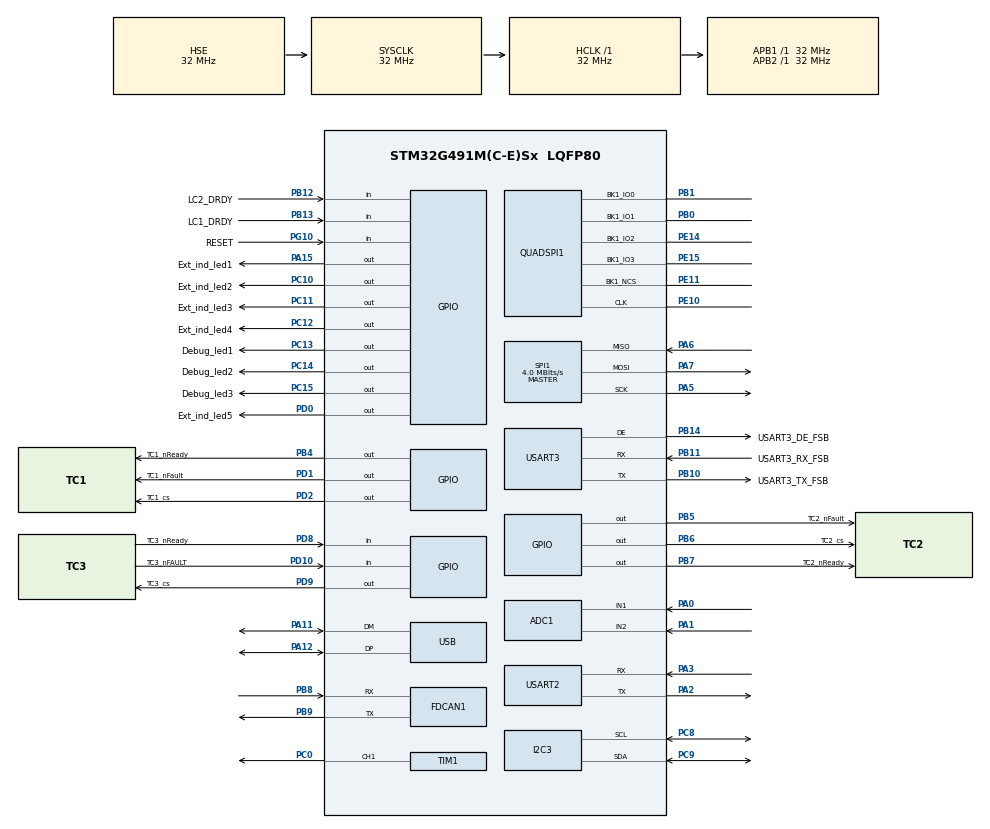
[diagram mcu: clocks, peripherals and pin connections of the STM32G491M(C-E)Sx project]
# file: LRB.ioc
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ADC1.Channel-0\#ChannelRegularConversion=ADC_CHANNEL_1
ADC1.NbrOfConversionFlag=1
ADC1.OffsetNumber-0\#ChannelRegularConversion=ADC_OFFSET_NONE
ADC1.Rank-0\#ChannelRegularConversion=1
ADC1.SamplingTime-0\#ChannelRegularConversion=ADC_SAMPLETIME_2CYCLES_5
ADC1.SingleDiff-0\#ChannelRegularConversion=ADC_DIFFERENTIAL_ENDED
ADC1.master=1
Dma.I2C3_RX.0.Direction=DMA_PERIPH_TO_MEMORY
Dma.I2C3_RX.0.EventEnable=DISABLE
Dma.I2C3_RX.0.Instance=DMA1_Channel1
Dma.I2C3_RX.0.MemDataAlignment=DMA_MDATAALIGN_BYTE
Dma.I2C3_RX.0.MemInc=DMA_MINC_ENABLE
Dma.I2C3_RX.0.Mode=DMA_NORMAL
Dma.I2C3_RX.0.PeriphDataAlignment=DMA_PDATAALIGN_BYTE
Dma.I2C3_RX.0.PeriphInc=DMA_PINC_DISABLE
Dma.I2C3_RX.0.Polarity=HAL_DMAMUX_REQ_GEN_RISING
Dma.I2C3_RX.0.Priority=DMA_PRIORITY_LOW
Dma.I2C3_RX.0.RequestNumber=1
Dma.I2C3_RX.0.SignalID=NONE
Dma.I2C3_RX.0.SyncEnable=DISABLE
Dma.I2C3_RX.0.SyncPolarity=HAL_DMAMUX_SYNC_NO_EVENT
Dma.I2C3_RX.0.SyncRequestNumber=1
Dma.I2C3_RX.0.SyncSignalID=NONE
Dma.I2C3_TX.1.Direction=DMA_MEMORY_TO_PERIPH
Dma.I2C3_TX.1.EventEnable=DISABLE
Dma.I2C3_TX.1.Instance=DMA1_Channel2
Dma.I2C3_TX.1.MemDataAlignment=DMA_MDATAALIGN_BYTE
Dma.I2C3_TX.1.MemInc=DMA_MINC_ENABLE
Dma.I2C3_TX.1.Mode=DMA_NORMAL
Dma.I2C3_TX.1.PeriphDataAlignment=DMA_PDATAALIGN_BYTE
Dma.I2C3_TX.1.PeriphInc=DMA_PINC_DISABLE
Dma.I2C3_TX.1.Polarity=HAL_DMAMUX_REQ_GEN_RISING
Dma.I2C3_TX.1.Priority=DMA_PRIORITY_LOW
Dma.I2C3_TX.1.RequestNumber=1
Dma.I2C3_TX.1.SignalID=NONE
Dma.I2C3_TX.1.SyncEnable=DISABLE
Dma.I2C3_TX.1.SyncPolarity=HAL_DMAMUX_SYNC_NO_EVENT
Dma.I2C3_TX.1.SyncRequestNumber=1
Dma.I2C3_TX.1.SyncSignalID=NONE
Dma.Request0=I2C3_RX
Dma.Request1=I2C3_TX
Dma.Request2=SPI1_RX
Dma.Request3=SPI1_TX
Dma.SPI1_RX.2.Direction=DMA_PERIPH_TO_MEMORY
Dma.SPI1_RX.2.EventEnable=DISABLE
Dma.SPI1_RX.2.Instance=DMA1_Channel3
Dma.SPI1_RX.2.MemDataAlignment=DMA_MDATAALIGN_BYTE
Dma.SPI1_RX.2.MemInc=DMA_MINC_ENABLE
Dma.SPI1_RX.2.Mode=DMA_NORMAL
Dma.SPI1_RX.2.PeriphDataAlignment=DMA_PDATAALIGN_BYTE
Dma.SPI1_RX.2.PeriphInc=DMA_PINC_DISABLE
Dma.SPI1_RX.2.Polarity=HAL_DMAMUX_REQ_GEN_RISING
Dma.SPI1_RX.2.Priority=DMA_PRIORITY_LOW
Dma.SPI1_RX.2.RequestNumber=1
Dma.SPI1_RX.2.SignalID=NONE
Dma.SPI1_RX.2.SyncEnable=DISABLE
Dma.SPI1_RX.2.SyncPolarity=HAL_DMAMUX_SYNC_NO_EVENT
Dma.SPI1_RX.2.SyncRequestNumber=1
Dma.SPI1_RX.2.SyncSignalID=NONE
Dma.SPI1_TX.3.Direction=DMA_MEMORY_TO_PERIPH
Dma.SPI1_TX.3.EventEnable=DISABLE
Dma.SPI1_TX.3.Instance=DMA1_Channel4
Dma.SPI1_TX.3.MemDataAlignment=DMA_MDATAALIGN_BYTE
Dma.SPI1_TX.3.MemInc=DMA_MINC_ENABLE
Dma.SPI1_TX.3.Mode=DMA_NORMAL
Dma.SPI1_TX.3.PeriphDataAlignment=DMA_PDATAALIGN_BYTE
Dma.SPI1_TX.3.PeriphInc=DMA_PINC_DISABLE
Dma.SPI1_TX.3.Polarity=HAL_DMAMUX_REQ_GEN_RISING
Dma.SPI1_TX.3.Priority=DMA_PRIORITY_LOW
Dma.SPI1_TX.3.RequestNumber=1
Dma.SPI1_TX.3.SignalID=NONE
Dma.SPI1_TX.3.SyncEnable=DISABLE
Dma.SPI1_TX.3.SyncPolarity=HAL_DMAMUX_SYNC_NO_EVENT
Dma.SPI1_TX.3.SyncRequestNumber=1
Dma.SPI1_TX.3.SyncSignalID=NONE
FDCAN1.CalculateBaudRateNominal=666666
FDCAN1.CalculateTimeBitNominal=1500
FDCAN1.CalculateTimeQuantumNominal=500.0
FREERTOS.Tasks01=defaultTask,0,192,StartDefaultTask,Default,NULL,Dynamic,NULL,NULL
FREERTOS.configMINIMAL_STACK_SIZE=192
FREERTOS.configTOTAL_HEAP_SIZE=65536
FREERTOS.configUSE_NEWLIB_REENTRANT=1
FREERTOS.configUSE_TIMERS=1
I2C3.Timing=0x00B07CB4
Mcu.Family=STM32G4
Mcu.Name=STM32G491M(C-E)Sx
Mcu.Package=LQFP80
NVIC.DMA1_Channel1_IRQn=true\:5\:0\:false\:false\:true\:true\:false\:true\:true
NVIC.DMA1_Channel2_IRQn=true\:5\:0\:false\:false\:true\:true\:false\:true\:true
NVIC.DMA1_Channel3_IRQn=true\:5\:0\:false\:false\:true\:true\:false\:true\:true
NVIC.DMA1_Channel4_IRQn=true\:5\:0\:false\:false\:true\:true\:false\:true\:true
NVIC.I2C3_ER_IRQn=true\:5\:0\:false\:false\:true\:true\:true\:true\:true
NVIC.I2C3_EV_IRQn=true\:5\:0\:false\:false\:true\:true\:true\:true\:true
NVIC.PriorityGroup=NVIC_PRIORITYGROUP_4
NVIC.SPI1_IRQn=true\:5\:0\:false\:false\:true\:true\:true\:true\:true
NVIC.TIM2_IRQn=true\:15\:0\:false\:false\:true\:false\:false\:true\:true
NVIC.TimeBase=TIM2_IRQn
NVIC.TimeBaseIP=TIM2
NVIC.USART2_IRQn=true\:5\:0\:false\:false\:true\:true\:true\:true\:true
PA0.Mode=IN1-Differential
PA0.Signal=ADC1_IN1
PA1.Mode=IN1-Differential
PA1.Signal=ADC1_IN2
PA11.Mode=Device
PA11.Signal=USB_DM
PA12.Mode=Device
PA12.Signal=USB_DP
PA13.Mode=Trace_Asynchronous_SW
PA13.Signal=SYS_JTMS-SWDIO
PA14.Mode=Trace_Asynchronous_SW
PA14.Signal=SYS_JTCK-SWCLK
PA15.GPIO_Label=Ext_ind_led1
PA15.Signal=GPIO_Output
PA2.Mode=Asynchronous
PA2.Signal=USART2_TX
PA3.Mode=Asynchronous
PA3.Signal=USART2_RX
PA5.GPIO_Speed=GPIO_SPEED_FREQ_VERY_HIGH
PA5.Mode=Full_Duplex_Master
PA5.Signal=SPI1_SCK
PA6.GPIO_Speed=GPIO_SPEED_FREQ_VERY_HIGH
PA6.Mode=Full_Duplex_Master
PA6.Signal=SPI1_MISO
PA7.GPIO_Speed=GPIO_SPEED_FREQ_VERY_HIGH
PA7.Mode=Full_Duplex_Master
PA7.Signal=SPI1_MOSI
PB0.Mode=Single Bank 1
PB0.Signal=QUADSPI1_BK1_IO1
PB1.Mode=Single Bank 1
PB1.Signal=QUADSPI1_BK1_IO0
PB10.GPIO_Label=USART3_TX_FSB
PB10.Mode=Asynchronous
PB10.Signal=USART3_TX
PB11.GPIO_Label=USART3_RX_FSB
PB11.Mode=Asynchronous
PB11.Signal=USART3_RX
PB12.GPIO_Label=LC2_DRDY
PB12.Signal=GPIO_Input
PB13.GPIO_Label=LC1_DRDY
PB13.Signal=GPIO_Input
PB14.GPIO_Label=USART3_DE_FSB
PB14.Mode=Hardware Flow Control (RS485)
PB14.Signal=USART3_DE
PB3.Mode=Trace_Asynchronous_SW
PB3.Signal=SYS_JTDO-SWO
PB4.GPIO_Label=TC1_nReady
PB4.Signal=GPIO_Output
PB5.GPIO_Label=TC2_nFault
PB5.Signal=GPIO_Output
PB6.GPIO_Label=TC2_cs
PB6.Signal=GPIO_Output
PB7.GPIO_Label=TC2_nReady
PB7.Signal=GPIO_Output
PB8-BOOT0.Mode=FDCAN_Activate
PB8-BOOT0.Signal=FDCAN1_RX
PB9.Mode=FDCAN_Activate
PB9.Signal=FDCAN1_TX
PC0.Signal=S_TIM1_CH1
PC10.GPIO_Label=Ext_ind_led2
PC10.Signal=GPIO_Output
PC11.GPIO_Label=Ext_ind_led3
PC11.Signal=GPIO_Output
PC12.GPIO_Label=Ext_ind_led4
PC12.Signal=GPIO_Output
PC13.GPIO_Label=Debug_led1
PC13.Signal=GPIO_Output
PC14-OSC32_IN.GPIO_Label=Debug_led2
PC14-OSC32_IN.Signal=GPIO_Output
PC15-OSC32_OUT.GPIO_Label=Debug_led3
PC15-OSC32_OUT.Signal=GPIO_Output
PC8.GPIO_Pu=GPIO_PULLUP
PC8.GPIO_Speed=GPIO_SPEED_FREQ_VERY_HIGH
PC8.Mode=I2C
PC8.Signal=I2C3_SCL
PC9.GPIO_Pu=GPIO_PULLUP
PC9.GPIO_Speed=GPIO_SPEED_FREQ_VERY_HIGH
PC9.Mode=I2C
PC9.Signal=I2C3_SDA
PD0.GPIO_Label=Ext_ind_led5
PD0.Signal=GPIO_Output
PD1.GPIO_Label=TC1_nFault
PD1.Signal=GPIO_Output
PD10.GPIO_Label=TC3_nFAULT
PD10.Signal=GPIO_Input
PD2.GPIO_Label=TC1_cs
PD2.Signal=GPIO_Output
PD8.GPIO_Label=TC3_nReady
PD8.Signal=GPIO_Input
PD9.GPIO_Label=TC3_cs
PD9.Signal=GPIO_Output
PE10.Mode=Single Bank 1
PE10.Signal=QUADSPI1_CLK
PE11.Mode=Single Bank 1
PE11.Signal=QUADSPI1_BK1_NCS
PE14.Mode=Single Bank 1
PE14.Signal=QUADSPI1_BK1_IO2
PE15.Mode=Single Bank 1
PE15.Signal=QUADSPI1_BK1_IO3
PF0-OSC_IN.Mode=HSE-External-Oscillator
PF0-OSC_IN.Signal=RCC_OSC_IN
PF1-OSC_OUT.Mode=HSE-External-Oscillator
PF1-OSC_OUT.Signal=RCC_OSC_OUT
PG10-NRST.GPIO_Label=RESET
PG10-NRST.Signal=GPIO_Input
ProjectManager.HeapSize=0x200
ProjectManager.StackSize=0x400
ProjectManager.TargetToolchain=STM32CubeIDE
RCC.ADC12Freq_Value=32000000
RCC.ADC345Freq_Value=32000000
RCC.AHBFreq_Value=32000000
RCC.APB1Freq_Value=32000000
RCC.APB1TimFreq_Value=32000000
RCC.APB2Freq_Value=32000000
RCC.APB2TimFreq_Value=32000000
RCC.CortexFreq_Value=32000000
RCC.EXTERNAL_CLOCK_VALUE=12288000
RCC.HCLKFreq_Value=32000000
RCC.HSE_VALUE=32000000
RCC.HSI48_VALUE=48000000
RCC.HSI_VALUE=16000000
RCC.LSE_VALUE=32768
RCC.PLLSourceVirtual=RCC_PLLSOURCE_HSE
RCC.SYSCLKFreq_VALUE=32000000
RCC.SYSCLKSource=RCC_SYSCLKSOURCE_HSE
RCC.VCOOutputFreq_Value=256000000
SH.S_TIM1_CH1.0=TIM1_CH1,PWM Generation1 CH1
SPI1.BaudRatePrescaler=SPI_BAUDRATEPRESCALER_8
SPI1.CLKPhase=SPI_PHASE_2EDGE
SPI1.CLKPolarity=SPI_POLARITY_HIGH
SPI1.CalculateBaudRate=4.0 MBits/s
SPI1.DataSize=SPI_DATASIZE_8BIT
SPI1.Direction=SPI_DIRECTION_2LINES
SPI1.Mode=SPI_MODE_MASTER
SPI1.VirtualType=VM_MASTER
TIM1.Channel-PWM\ Generation1\ CH1=TIM_CHANNEL_1
TIM3.Prescaler=10000
USART2.VirtualMode-Asynchronous=VM_ASYNC
USART3.VirtualMode-Asynchronous=VM_ASYNC
USART3.VirtualMode-Hardware\ Flow\ Control\ (RS485)=VM_ASYNC
VP_CRC_VS_CRC.Mode=CRC_Activate
VP_FREERTOS_VS_CMSIS_V1.Mode=CMSIS_V1
VP_SYS_VS_DBSignals.Mode=DisableDeadBatterySignals
VP_SYS_VS_tim2.Mode=TIM2
VP_TIM3_VS_ClockSourceINT.Mode=Internal
board=custom

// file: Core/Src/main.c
/* USER CODE BEGIN Header */
/**
  ******************************************************************************
  * @file           : main.c
  * @brief          : Main program body
  ******************************************************************************
  * @attention
  *
  * Copyright (c) 2026 STMicroelectronics.
  * All rights reserved.
  *
  * This software is licensed under terms that can be found in the LICENSE file
  * in the root directory of this software component.
  * If no LICENSE file comes with this software, it is provided AS-IS.
  *
  ******************************************************************************
  */
/* USER CODE END Header */
#include "main.h"
#include "cmsis_os.h"

/* USER CODE BEGIN Includes */
#include "RunInterface.hpp"
//#define USE_FULL_LL_DRIVER
/* USER CODE END Includes */

ADC_HandleTypeDef hadc1;

CRC_HandleTypeDef hcrc;

FDCAN_HandleTypeDef hfdcan1;

I2C_HandleTypeDef hi2c3;
DMA_HandleTypeDef hdma_i2c3_rx;
DMA_HandleTypeDef hdma_i2c3_tx;

QSPI_HandleTypeDef hqspi1;

SPI_HandleTypeDef hspi1;
DMA_HandleTypeDef hdma_spi1_rx;
DMA_HandleTypeDef hdma_spi1_tx;

TIM_HandleTypeDef htim1;
TIM_HandleTypeDef htim3;

UART_HandleTypeDef huart3;

PCD_HandleTypeDef hpcd_USB_FS;

osThreadId defaultTaskHandle;

void SystemClock_Config(void);
static void MX_GPIO_Init(void);
static void MX_DMA_Init(void);
static void MX_QUADSPI1_Init(void);
static void MX_SPI1_Init(void);
static void MX_USB_PCD_Init(void);
static void MX_USART2_UART_Init(void);
static void MX_USART3_UART_Init(void);
static void MX_ADC1_Init(void);
static void MX_I2C3_Init(void);
static void MX_TIM1_Init(void);
static void MX_CRC_Init(void);
static void MX_TIM3_Init(void);
static void MX_FDCAN1_Init(void);
void StartDefaultTask(void const * argument);

int main(void)
{

  /* MCU Configuration--------------------------------------------------------*/

  /* Reset of all peripherals, Initializes the Flash interface and the Systick. */
  HAL_Init();

  /* Configure the system clock */
  SystemClock_Config();

  /* Initialize all configured peripherals */
  MX_GPIO_Init();
  MX_DMA_Init();
  MX_QUADSPI1_Init();
  MX_SPI1_Init();
  MX_USB_PCD_Init();
  MX_USART2_UART_Init();
  MX_USART3_UART_Init();
  MX_ADC1_Init();
  MX_I2C3_Init();
  MX_TIM1_Init();
  MX_CRC_Init();
  MX_TIM3_Init();
  MX_FDCAN1_Init();
  /* USER CODE BEGIN 2 */
#if (configGENERATE_RUN_TIME_STATS == 1)
  MX_TIM3_Init();		// Replace TIM2 with your selected timer
#endif
  /* USER CODE END 2 */

  /* Create the thread(s) */
  /* definition and creation of defaultTask */
  osThreadDef(defaultTask, StartDefaultTask, osPriorityNormal, 0, 192);
  defaultTaskHandle = osThreadCreate(osThread(defaultTask), NULL);

  /* USER CODE BEGIN RTOS_THREADS */
  /* add threads, ... */
  run_interface();
  /* USER CODE END RTOS_THREADS */

  /* Start scheduler */
  osKernelStart();

  /* We should never get here as control is now taken by the scheduler */

  /* Infinite loop */
  while (1)
  {

  }
}

void SystemClock_Config(void)
{
  RCC_OscInitTypeDef RCC_OscInitStruct = {0};
  RCC_ClkInitTypeDef RCC_ClkInitStruct = {0};

  /** Configure the main internal regulator output voltage
  */
  HAL_PWREx_ControlVoltageScaling(PWR_REGULATOR_VOLTAGE_SCALE1);

  /** Initializes the RCC Oscillators according to the specified parameters
  * in the RCC_OscInitTypeDef structure.
  */
  RCC_OscInitStruct.OscillatorType = RCC_OSCILLATORTYPE_HSI48|RCC_OSCILLATORTYPE_HSE;
  RCC_OscInitStruct.HSEState = RCC_HSE_ON;
  RCC_OscInitStruct.HSI48State = RCC_HSI48_ON;
  RCC_OscInitStruct.PLL.PLLState = RCC_PLL_NONE;
  if (HAL_RCC_OscConfig(&RCC_OscInitStruct) != HAL_OK)
  {
    Error_Handler();
  }

  /** Initializes the CPU, AHB and APB buses clocks
  */
  RCC_ClkInitStruct.ClockType = RCC_CLOCKTYPE_HCLK|RCC_CLOCKTYPE_SYSCLK
                              |RCC_CLOCKTYPE_PCLK1|RCC_CLOCKTYPE_PCLK2;
  RCC_ClkInitStruct.SYSCLKSource = RCC_SYSCLKSOURCE_HSE;
  RCC_ClkInitStruct.AHBCLKDivider = RCC_SYSCLK_DIV1;
  RCC_ClkInitStruct.APB1CLKDivider = RCC_HCLK_DIV1;
  RCC_ClkInitStruct.APB2CLKDivider = RCC_HCLK_DIV1;

  if (HAL_RCC_ClockConfig(&RCC_ClkInitStruct, FLASH_LATENCY_1) != HAL_OK)
  {
    Error_Handler();
  }
}

static void MX_ADC1_Init(void)
{

  ADC_MultiModeTypeDef multimode = {0};
  ADC_ChannelConfTypeDef sConfig = {0};

  /** Common config
  */
  hadc1.Instance = ADC1;
  hadc1.Init.ClockPrescaler = ADC_CLOCK_SYNC_PCLK_DIV2;
  hadc1.Init.Resolution = ADC_RESOLUTION_12B;
  hadc1.Init.DataAlign = ADC_DATAALIGN_RIGHT;
  hadc1.Init.GainCompensation = 0;
  hadc1.Init.ScanConvMode = ADC_SCAN_DISABLE;
  hadc1.Init.EOCSelection = ADC_EOC_SINGLE_CONV;
  hadc1.Init.LowPowerAutoWait = DISABLE;
  hadc1.Init.ContinuousConvMode = DISABLE;
  hadc1.Init.NbrOfConversion = 1;
  hadc1.Init.DiscontinuousConvMode = DISABLE;
  hadc1.Init.ExternalTrigConv = ADC_SOFTWARE_START;
  hadc1.Init.ExternalTrigConvEdge = ADC_EXTERNALTRIGCONVEDGE_NONE;
  hadc1.Init.DMAContinuousRequests = DISABLE;
  hadc1.Init.Overrun = ADC_OVR_DATA_PRESERVED;
  hadc1.Init.OversamplingMode = DISABLE;
  if (HAL_ADC_Init(&hadc1) != HAL_OK)
  {
    Error_Handler();
  }

  /** Configure the ADC multi-mode
  */
  multimode.Mode = ADC_MODE_INDEPENDENT;
  if (HAL_ADCEx_MultiModeConfigChannel(&hadc1, &multimode) != HAL_OK)
  {
    Error_Handler();
  }

  /** Configure Regular Channel
  */
  sConfig.Channel = ADC_CHANNEL_1;
  sConfig.Rank = ADC_REGULAR_RANK_1;
  sConfig.SamplingTime = ADC_SAMPLETIME_2CYCLES_5;
  sConfig.SingleDiff = ADC_DIFFERENTIAL_ENDED;
  sConfig.OffsetNumber = ADC_OFFSET_NONE;
  sConfig.Offset = 0;
  if (HAL_ADC_ConfigChannel(&hadc1, &sConfig) != HAL_OK)
  {
    Error_Handler();
  }

}

static void MX_CRC_Init(void)
{

  hcrc.Instance = CRC;
  hcrc.Init.DefaultPolynomialUse = DEFAULT_POLYNOMIAL_ENABLE;
  hcrc.Init.DefaultInitValueUse = DEFAULT_INIT_VALUE_ENABLE;
  hcrc.Init.InputDataInversionMode = CRC_INPUTDATA_INVERSION_NONE;
  hcrc.Init.OutputDataInversionMode = CRC_OUTPUTDATA_INVERSION_DISABLE;
  hcrc.InputDataFormat = CRC_INPUTDATA_FORMAT_BYTES;
  if (HAL_CRC_Init(&hcrc) != HAL_OK)
  {
    Error_Handler();
  }

}

static void MX_FDCAN1_Init(void)
{

  hfdcan1.Instance = FDCAN1;
  hfdcan1.Init.ClockDivider = FDCAN_CLOCK_DIV1;
  hfdcan1.Init.FrameFormat = FDCAN_FRAME_CLASSIC;
  hfdcan1.Init.Mode = FDCAN_MODE_NORMAL;
  hfdcan1.Init.AutoRetransmission = DISABLE;
  hfdcan1.Init.TransmitPause = DISABLE;
  hfdcan1.Init.ProtocolException = DISABLE;
  hfdcan1.Init.NominalPrescaler = 16;
  hfdcan1.Init.NominalSyncJumpWidth = 1;
  hfdcan1.Init.NominalTimeSeg1 = 1;
  hfdcan1.Init.NominalTimeSeg2 = 1;
  hfdcan1.Init.DataPrescaler = 1;
  hfdcan1.Init.DataSyncJumpWidth = 1;
  hfdcan1.Init.DataTimeSeg1 = 1;
  hfdcan1.Init.DataTimeSeg2 = 1;
  hfdcan1.Init.StdFiltersNbr = 0;
  hfdcan1.Init.ExtFiltersNbr = 0;
  hfdcan1.Init.TxFifoQueueMode = FDCAN_TX_FIFO_OPERATION;
  if (HAL_FDCAN_Init(&hfdcan1) != HAL_OK)
  {
    Error_Handler();
  }

}

static void MX_I2C3_Init(void)
{

  hi2c3.Instance = I2C3;
  hi2c3.Init.Timing = 0x00B07CB4;
  hi2c3.Init.OwnAddress1 = 0;
  hi2c3.Init.AddressingMode = I2C_ADDRESSINGMODE_7BIT;
  hi2c3.Init.DualAddressMode = I2C_DUALADDRESS_DISABLE;
  hi2c3.Init.OwnAddress2 = 0;
  hi2c3.Init.OwnAddress2Masks = I2C_OA2_NOMASK;
  hi2c3.Init.GeneralCallMode = I2C_GENERALCALL_DISABLE;
  hi2c3.Init.NoStretchMode = I2C_NOSTRETCH_DISABLE;
  if (HAL_I2C_Init(&hi2c3) != HAL_OK)
  {
    Error_Handler();
  }

  /** Configure Analogue filter
  */
  if (HAL_I2CEx_ConfigAnalogFilter(&hi2c3, I2C_ANALOGFILTER_ENABLE) != HAL_OK)
  {
    Error_Handler();
  }

  /** Configure Digital filter
  */
  if (HAL_I2CEx_ConfigDigitalFilter(&hi2c3, 0) != HAL_OK)
  {
    Error_Handler();
  }

}

static void MX_QUADSPI1_Init(void)
{

  /* QUADSPI1 parameter configuration*/
  hqspi1.Instance = QUADSPI;
  hqspi1.Init.ClockPrescaler = 255;
  hqspi1.Init.FifoThreshold = 1;
  hqspi1.Init.SampleShifting = QSPI_SAMPLE_SHIFTING_NONE;
  hqspi1.Init.FlashSize = 1;
  hqspi1.Init.ChipSelectHighTime = QSPI_CS_HIGH_TIME_1_CYCLE;
  hqspi1.Init.ClockMode = QSPI_CLOCK_MODE_0;
  hqspi1.Init.FlashID = QSPI_FLASH_ID_1;
  hqspi1.Init.DualFlash = QSPI_DUALFLASH_DISABLE;
  if (HAL_QSPI_Init(&hqspi1) != HAL_OK)
  {
    Error_Handler();
  }

}

static void MX_SPI1_Init(void)
{

  /* SPI1 parameter configuration*/
  hspi1.Instance = SPI1;
  hspi1.Init.Mode = SPI_MODE_MASTER;
  hspi1.Init.Direction = SPI_DIRECTION_2LINES;
  hspi1.Init.DataSize = SPI_DATASIZE_8BIT;
  hspi1.Init.CLKPolarity = SPI_POLARITY_HIGH;
  hspi1.Init.CLKPhase = SPI_PHASE_2EDGE;
  hspi1.Init.NSS = SPI_NSS_SOFT;
  hspi1.Init.BaudRatePrescaler = SPI_BAUDRATEPRESCALER_8;
  hspi1.Init.FirstBit = SPI_FIRSTBIT_MSB;
  hspi1.Init.TIMode = SPI_TIMODE_DISABLE;
  hspi1.Init.CRCCalculation = SPI_CRCCALCULATION_DISABLE;
  hspi1.Init.CRCPolynomial = 7;
  hspi1.Init.CRCLength = SPI_CRC_LENGTH_DATASIZE;
  hspi1.Init.NSSPMode = SPI_NSS_PULSE_DISABLE;
  if (HAL_SPI_Init(&hspi1) != HAL_OK)
  {
    Error_Handler();
  }

}

static void MX_TIM1_Init(void)
{

  TIM_MasterConfigTypeDef sMasterConfig = {0};
  TIM_OC_InitTypeDef sConfigOC = {0};
  TIM_BreakDeadTimeConfigTypeDef sBreakDeadTimeConfig = {0};

  htim1.Instance = TIM1;
  htim1.Init.Prescaler = 0;
  htim1.Init.CounterMode = TIM_COUNTERMODE_UP;
  htim1.Init.Period = 65535;
  htim1.Init.ClockDivision = TIM_CLOCKDIVISION_DIV1;
  htim1.Init.RepetitionCounter = 0;
  htim1.Init.AutoReloadPreload = TIM_AUTORELOAD_PRELOAD_DISABLE;
  if (HAL_TIM_PWM_Init(&htim1) != HAL_OK)
  {
    Error_Handler();
  }
  sMasterConfig.MasterOutputTrigger = TIM_TRGO_RESET;
  sMasterConfig.MasterOutputTrigger2 = TIM_TRGO2_RESET;
  sMasterConfig.MasterSlaveMode = TIM_MASTERSLAVEMODE_DISABLE;
  if (HAL_TIMEx_MasterConfigSynchronization(&htim1, &sMasterConfig) != HAL_OK)
  {
    Error_Handler();
  }
  sConfigOC.OCMode = TIM_OCMODE_PWM1;
  sConfigOC.Pulse = 0;
  sConfigOC.OCPolarity = TIM_OCPOLARITY_HIGH;
  sConfigOC.OCNPolarity = TIM_OCNPOLARITY_HIGH;
  sConfigOC.OCFastMode = TIM_OCFAST_DISABLE;
  sConfigOC.OCIdleState = TIM_OCIDLESTATE_RESET;
  sConfigOC.OCNIdleState = TIM_OCNIDLESTATE_RESET;
  if (HAL_TIM_PWM_ConfigChannel(&htim1, &sConfigOC, TIM_CHANNEL_1) != HAL_OK)
  {
    Error_Handler();
  }
  sBreakDeadTimeConfig.OffStateRunMode = TIM_OSSR_DISABLE;
  sBreakDeadTimeConfig.OffStateIDLEMode = TIM_OSSI_DISABLE;
  sBreakDeadTimeConfig.LockLevel = TIM_LOCKLEVEL_OFF;
  sBreakDeadTimeConfig.DeadTime = 0;
  sBreakDeadTimeConfig.BreakState = TIM_BREAK_DISABLE;
  sBreakDeadTimeConfig.BreakPolarity = TIM_BREAKPOLARITY_HIGH;
  sBreakDeadTimeConfig.BreakFilter = 0;
  sBreakDeadTimeConfig.BreakAFMode = TIM_BREAK_AFMODE_INPUT;
  sBreakDeadTimeConfig.Break2State = TIM_BREAK2_DISABLE;
  sBreakDeadTimeConfig.Break2Polarity = TIM_BREAK2POLARITY_HIGH;
  sBreakDeadTimeConfig.Break2Filter = 0;
  sBreakDeadTimeConfig.Break2AFMode = TIM_BREAK_AFMODE_INPUT;
  sBreakDeadTimeConfig.AutomaticOutput = TIM_AUTOMATICOUTPUT_DISABLE;
  if (HAL_TIMEx_ConfigBreakDeadTime(&htim1, &sBreakDeadTimeConfig) != HAL_OK)
  {
    Error_Handler();
  }
  HAL_TIM_MspPostInit(&htim1);

}

static void MX_TIM3_Init(void)
{

  TIM_ClockConfigTypeDef sClockSourceConfig = {0};
  TIM_MasterConfigTypeDef sMasterConfig = {0};

  htim3.Instance = TIM3;
  htim3.Init.Prescaler = 10000;
  htim3.Init.CounterMode = TIM_COUNTERMODE_UP;
  htim3.Init.Period = 65535;
  htim3.Init.ClockDivision = TIM_CLOCKDIVISION_DIV1;
  htim3.Init.AutoReloadPreload = TIM_AUTORELOAD_PRELOAD_DISABLE;
  if (HAL_TIM_Base_Init(&htim3) != HAL_OK)
  {
    Error_Handler();
  }
  sClockSourceConfig.ClockSource = TIM_CLOCKSOURCE_INTERNAL;
  if (HAL_TIM_ConfigClockSource(&htim3, &sClockSourceConfig) != HAL_OK)
  {
    Error_Handler();
  }
  sMasterConfig.MasterOutputTrigger = TIM_TRGO_RESET;
  sMasterConfig.MasterSlaveMode = TIM_MASTERSLAVEMODE_DISABLE;
  if (HAL_TIMEx_MasterConfigSynchronization(&htim3, &sMasterConfig) != HAL_OK)
  {
    Error_Handler();
  }

}

static void MX_USART2_UART_Init(void)
{

  LL_USART_InitTypeDef USART_InitStruct = {0};

  LL_GPIO_InitTypeDef GPIO_InitStruct = {0};
  RCC_PeriphCLKInitTypeDef PeriphClkInit = {0};

  /** Initializes the peripherals clocks
  */
  PeriphClkInit.PeriphClockSelection = RCC_PERIPHCLK_USART2;
  PeriphClkInit.Usart2ClockSelection = RCC_USART2CLKSOURCE_PCLK1;
  if (HAL_RCCEx_PeriphCLKConfig(&PeriphClkInit) != HAL_OK)
  {
    Error_Handler();
  }

  /* Peripheral clock enable */
  LL_APB1_GRP1_EnableClock(LL_APB1_GRP1_PERIPH_USART2);

  LL_AHB2_GRP1_EnableClock(LL_AHB2_GRP1_PERIPH_GPIOA);
  /**USART2 GPIO Configuration
  PA2   ------> USART2_TX
  PA3   ------> USART2_RX
  */
  GPIO_InitStruct.Pin = LL_GPIO_PIN_2;
  GPIO_InitStruct.Mode = LL_GPIO_MODE_ALTERNATE;
  GPIO_InitStruct.Speed = LL_GPIO_SPEED_FREQ_LOW;
  GPIO_InitStruct.OutputType = LL_GPIO_OUTPUT_PUSHPULL;
  GPIO_InitStruct.Pull = LL_GPIO_PULL_NO;
  GPIO_InitStruct.Alternate = LL_GPIO_AF_7;
  LL_GPIO_Init(GPIOA, &GPIO_InitStruct);

  GPIO_InitStruct.Pin = LL_GPIO_PIN_3;
  GPIO_InitStruct.Mode = LL_GPIO_MODE_ALTERNATE;
  GPIO_InitStruct.Speed = LL_GPIO_SPEED_FREQ_LOW;
  GPIO_InitStruct.OutputType = LL_GPIO_OUTPUT_PUSHPULL;
  GPIO_InitStruct.Pull = LL_GPIO_PULL_NO;
  GPIO_InitStruct.Alternate = LL_GPIO_AF_7;
  LL_GPIO_Init(GPIOA, &GPIO_InitStruct);

  /* USART2 interrupt Init */
  NVIC_SetPriority(USART2_IRQn, NVIC_EncodePriority(NVIC_GetPriorityGrouping(),5, 0));
  NVIC_EnableIRQ(USART2_IRQn);

  USART_InitStruct.PrescalerValue = LL_USART_PRESCALER_DIV1;
  USART_InitStruct.BaudRate = 115200;
  USART_InitStruct.DataWidth = LL_USART_DATAWIDTH_8B;
  USART_InitStruct.StopBits = LL_USART_STOPBITS_1;
  USART_InitStruct.Parity = LL_USART_PARITY_NONE;
  USART_InitStruct.TransferDirection = LL_USART_DIRECTION_TX_RX;
  USART_InitStruct.HardwareFlowControl = LL_USART_HWCONTROL_NONE;
  USART_InitStruct.OverSampling = LL_USART_OVERSAMPLING_16;
  LL_USART_Init(USART2, &USART_InitStruct);
  LL_USART_SetTXFIFOThreshold(USART2, LL_USART_FIFOTHRESHOLD_1_8);
  LL_USART_SetRXFIFOThreshold(USART2, LL_USART_FIFOTHRESHOLD_1_8);
  LL_USART_DisableFIFO(USART2);
  LL_USART_ConfigAsyncMode(USART2);

  LL_USART_Enable(USART2);

  /* Polling USART2 initialisation */
  while((!(LL_USART_IsActiveFlag_TEACK(USART2))) || (!(LL_USART_IsActiveFlag_REACK(USART2))))
  {
  }

}

static void MX_USART3_UART_Init(void)
{

  huart3.Instance = USART3;
  huart3.Init.BaudRate = 115200;
  huart3.Init.WordLength = UART_WORDLENGTH_8B;
  huart3.Init.StopBits = UART_STOPBITS_1;
  huart3.Init.Parity = UART_PARITY_NONE;
  huart3.Init.Mode = UART_MODE_TX_RX;
  huart3.Init.HwFlowCtl = UART_HWCONTROL_NONE;
  huart3.Init.OverSampling = UART_OVERSAMPLING_16;
  huart3.Init.OneBitSampling = UART_ONE_BIT_SAMPLE_DISABLE;
  huart3.Init.ClockPrescaler = UART_PRESCALER_DIV1;
  huart3.AdvancedInit.AdvFeatureInit = UART_ADVFEATURE_NO_INIT;
  if (HAL_RS485Ex_Init(&huart3, UART_DE_POLARITY_HIGH, 0, 0) != HAL_OK)
  {
    Error_Handler();
  }
  if (HAL_UARTEx_SetTxFifoThreshold(&huart3, UART_TXFIFO_THRESHOLD_1_8) != HAL_OK)
  {
    Error_Handler();
  }
  if (HAL_UARTEx_SetRxFifoThreshold(&huart3, UART_RXFIFO_THRESHOLD_1_8) != HAL_OK)
  {
    Error_Handler();
  }
  if (HAL_UARTEx_DisableFifoMode(&huart3) != HAL_OK)
  {
    Error_Handler();
  }
  /* USER CODE BEGIN USART3_Init 2 */
  NVIC_SetPriority(USART3_IRQn, NVIC_EncodePriority(NVIC_GetPriorityGrouping(), 5, 0));
  NVIC_EnableIRQ(USART3_IRQn);
  /* USER CODE END USART3_Init 2 */

}

static void MX_USB_PCD_Init(void)
{

  hpcd_USB_FS.Instance = USB;
  hpcd_USB_FS.Init.dev_endpoints = 8;
  hpcd_USB_FS.Init.speed = PCD_SPEED_FULL;
  hpcd_USB_FS.Init.phy_itface = PCD_PHY_EMBEDDED;
  hpcd_USB_FS.Init.Sof_enable = DISABLE;
  hpcd_USB_FS.Init.low_power_enable = DISABLE;
  hpcd_USB_FS.Init.lpm_enable = DISABLE;
  hpcd_USB_FS.Init.battery_charging_enable = DISABLE;
  if (HAL_PCD_Init(&hpcd_USB_FS) != HAL_OK)
  {
    Error_Handler();
  }

}

static void MX_DMA_Init(void)
{

  /* DMA controller clock enable */
  __HAL_RCC_DMAMUX1_CLK_ENABLE();
  __HAL_RCC_DMA1_CLK_ENABLE();

  /* DMA interrupt init */
  /* DMA1_Channel1_IRQn interrupt configuration */
  HAL_NVIC_SetPriority(DMA1_Channel1_IRQn, 5, 0);
  HAL_NVIC_EnableIRQ(DMA1_Channel1_IRQn);
  /* DMA1_Channel2_IRQn interrupt configuration */
  HAL_NVIC_SetPriority(DMA1_Channel2_IRQn, 5, 0);
  HAL_NVIC_EnableIRQ(DMA1_Channel2_IRQn);
  /* DMA1_Channel3_IRQn interrupt configuration */
  HAL_NVIC_SetPriority(DMA1_Channel3_IRQn, 5, 0);
  HAL_NVIC_EnableIRQ(DMA1_Channel3_IRQn);
  /* DMA1_Channel4_IRQn interrupt configuration */
  HAL_NVIC_SetPriority(DMA1_Channel4_IRQn, 5, 0);
  HAL_NVIC_EnableIRQ(DMA1_Channel4_IRQn);

}

static void MX_GPIO_Init(void)
{
  LL_GPIO_InitTypeDef GPIO_InitStruct = {0};

  /* GPIO Ports Clock Enable */
  LL_AHB2_GRP1_EnableClock(LL_AHB2_GRP1_PERIPH_GPIOC);
  LL_AHB2_GRP1_EnableClock(LL_AHB2_GRP1_PERIPH_GPIOF);
  LL_AHB2_GRP1_EnableClock(LL_AHB2_GRP1_PERIPH_GPIOG);
  LL_AHB2_GRP1_EnableClock(LL_AHB2_GRP1_PERIPH_GPIOA);
  LL_AHB2_GRP1_EnableClock(LL_AHB2_GRP1_PERIPH_GPIOB);
  LL_AHB2_GRP1_EnableClock(LL_AHB2_GRP1_PERIPH_GPIOE);
  LL_AHB2_GRP1_EnableClock(LL_AHB2_GRP1_PERIPH_GPIOD);

  /**/
  LL_GPIO_ResetOutputPin(Debug_led1_GPIO_Port, Debug_led1_Pin);

  /**/
  LL_GPIO_ResetOutputPin(Debug_led2_GPIO_Port, Debug_led2_Pin);

  /**/
  LL_GPIO_ResetOutputPin(Debug_led3_GPIO_Port, Debug_led3_Pin);

  /**/
  LL_GPIO_ResetOutputPin(TC3_cs_GPIO_Port, TC3_cs_Pin);

  /**/
  LL_GPIO_ResetOutputPin(Ext_ind_led1_GPIO_Port, Ext_ind_led1_Pin);

  /**/
  LL_GPIO_ResetOutputPin(Ext_ind_led2_GPIO_Port, Ext_ind_led2_Pin);

  /**/
  LL_GPIO_ResetOutputPin(Ext_ind_led3_GPIO_Port, Ext_ind_led3_Pin);

  /**/
  LL_GPIO_ResetOutputPin(Ext_ind_led4_GPIO_Port, Ext_ind_led4_Pin);

  /**/
  LL_GPIO_ResetOutputPin(Ext_ind_led5_GPIO_Port, Ext_ind_led5_Pin);

  /**/
  LL_GPIO_ResetOutputPin(TC1_nFault_GPIO_Port, TC1_nFault_Pin);

  /**/
  LL_GPIO_ResetOutputPin(TC1_cs_GPIO_Port, TC1_cs_Pin);

  /**/
  LL_GPIO_ResetOutputPin(TC1_nReady_GPIO_Port, TC1_nReady_Pin);

  /**/
  LL_GPIO_ResetOutputPin(TC2_nFault_GPIO_Port, TC2_nFault_Pin);

  /**/
  LL_GPIO_ResetOutputPin(TC2_cs_GPIO_Port, TC2_cs_Pin);

  /**/
  LL_GPIO_ResetOutputPin(TC2_nReady_GPIO_Port, TC2_nReady_Pin);

  /**/
  GPIO_InitStruct.Pin = Debug_led1_Pin;
  GPIO_InitStruct.Mode = LL_GPIO_MODE_OUTPUT;
  GPIO_InitStruct.Speed = LL_GPIO_SPEED_FREQ_LOW;
  GPIO_InitStruct.OutputType = LL_GPIO_OUTPUT_PUSHPULL;
  GPIO_InitStruct.Pull = LL_GPIO_PULL_NO;
  LL_GPIO_Init(Debug_led1_GPIO_Port, &GPIO_InitStruct);

  /**/
  GPIO_InitStruct.Pin = Debug_led2_Pin;
  GPIO_InitStruct.Mode = LL_GPIO_MODE_OUTPUT;
  GPIO_InitStruct.Speed = LL_GPIO_SPEED_FREQ_LOW;
  GPIO_InitStruct.OutputType = LL_GPIO_OUTPUT_PUSHPULL;
  GPIO_InitStruct.Pull = LL_GPIO_PULL_NO;
  LL_GPIO_Init(Debug_led2_GPIO_Port, &GPIO_InitStruct);

  /**/
  GPIO_InitStruct.Pin = Debug_led3_Pin;
  GPIO_InitStruct.Mode = LL_GPIO_MODE_OUTPUT;
  GPIO_InitStruct.Speed = LL_GPIO_SPEED_FREQ_LOW;
  GPIO_InitStruct.OutputType = LL_GPIO_OUTPUT_PUSHPULL;
  GPIO_InitStruct.Pull = LL_GPIO_PULL_NO;
  LL_GPIO_Init(Debug_led3_GPIO_Port, &GPIO_InitStruct);

  /**/
  GPIO_InitStruct.Pin = RESET_Pin;
  GPIO_InitStruct.Mode = LL_GPIO_MODE_INPUT;
  GPIO_InitStruct.Pull = LL_GPIO_PULL_NO;
  LL_GPIO_Init(RESET_GPIO_Port, &GPIO_InitStruct);

  /**/
  GPIO_InitStruct.Pin = LC2_DRDY_Pin;
  GPIO_InitStruct.Mode = LL_GPIO_MODE_INPUT;
  GPIO_InitStruct.Pull = LL_GPIO_PULL_NO;
  LL_GPIO_Init(LC2_DRDY_GPIO_Port, &GPIO_InitStruct);

  /**/
  GPIO_InitStruct.Pin = LC1_DRDY_Pin;
  GPIO_InitStruct.Mode = LL_GPIO_MODE_INPUT;
  GPIO_InitStruct.Pull = LL_GPIO_PULL_NO;
  LL_GPIO_Init(LC1_DRDY_GPIO_Port, &GPIO_InitStruct);

  /**/
  GPIO_InitStruct.Pin = TC3_nReady_Pin;
  GPIO_InitStruct.Mode = LL_GPIO_MODE_INPUT;
  GPIO_InitStruct.Pull = LL_GPIO_PULL_NO;
  LL_GPIO_Init(TC3_nReady_GPIO_Port, &GPIO_InitStruct);

  /**/
  GPIO_InitStruct.Pin = TC3_cs_Pin;
  GPIO_InitStruct.Mode = LL_GPIO_MODE_OUTPUT;
  GPIO_InitStruct.Speed = LL_GPIO_SPEED_FREQ_LOW;
  GPIO_InitStruct.OutputType = LL_GPIO_OUTPUT_PUSHPULL;
  GPIO_InitStruct.Pull = LL_GPIO_PULL_NO;
  LL_GPIO_Init(TC3_cs_GPIO_Port, &GPIO_InitStruct);

  /**/
  GPIO_InitStruct.Pin = TC3_nFAULT_Pin;
  GPIO_InitStruct.Mode = LL_GPIO_MODE_INPUT;
  GPIO_InitStruct.Pull = LL_GPIO_PULL_NO;
  LL_GPIO_Init(TC3_nFAULT_GPIO_Port, &GPIO_InitStruct);

  /**/
  GPIO_InitStruct.Pin = Ext_ind_led1_Pin;
  GPIO_InitStruct.Mode = LL_GPIO_MODE_OUTPUT;
  GPIO_InitStruct.Speed = LL_GPIO_SPEED_FREQ_LOW;
  GPIO_InitStruct.OutputType = LL_GPIO_OUTPUT_PUSHPULL;
  GPIO_InitStruct.Pull = LL_GPIO_PULL_NO;
  LL_GPIO_Init(Ext_ind_led1_GPIO_Port, &GPIO_InitStruct);

  /**/
  GPIO_InitStruct.Pin = Ext_ind_led2_Pin;
  GPIO_InitStruct.Mode = LL_GPIO_MODE_OUTPUT;
  GPIO_InitStruct.Speed = LL_GPIO_SPEED_FREQ_LOW;
  GPIO_InitStruct.OutputType = LL_GPIO_OUTPUT_PUSHPULL;
  GPIO_InitStruct.Pull = LL_GPIO_PULL_NO;
  LL_GPIO_Init(Ext_ind_led2_GPIO_Port, &GPIO_InitStruct);

  /**/
  GPIO_InitStruct.Pin = Ext_ind_led3_Pin;
  GPIO_InitStruct.Mode = LL_GPIO_MODE_OUTPUT;
  GPIO_InitStruct.Speed = LL_GPIO_SPEED_FREQ_LOW;
  GPIO_InitStruct.OutputType = LL_GPIO_OUTPUT_PUSHPULL;
  GPIO_InitStruct.Pull = LL_GPIO_PULL_NO;
  LL_GPIO_Init(Ext_ind_led3_GPIO_Port, &GPIO_InitStruct);

  /**/
  GPIO_InitStruct.Pin = Ext_ind_led4_Pin;
  GPIO_InitStruct.Mode = LL_GPIO_MODE_OUTPUT;
  GPIO_InitStruct.Speed = LL_GPIO_SPEED_FREQ_LOW;
  GPIO_InitStruct.OutputType = LL_GPIO_OUTPUT_PUSHPULL;
  GPIO_InitStruct.Pull = LL_GPIO_PULL_NO;
  LL_GPIO_Init(Ext_ind_led4_GPIO_Port, &GPIO_InitStruct);

  /**/
  GPIO_InitStruct.Pin = Ext_ind_led5_Pin;
  GPIO_InitStruct.Mode = LL_GPIO_MODE_OUTPUT;
  GPIO_InitStruct.Speed = LL_GPIO_SPEED_FREQ_LOW;
  GPIO_InitStruct.OutputType = LL_GPIO_OUTPUT_PUSHPULL;
  GPIO_InitStruct.Pull = LL_GPIO_PULL_NO;
  LL_GPIO_Init(Ext_ind_led5_GPIO_Port, &GPIO_InitStruct);

  /**/
  GPIO_InitStruct.Pin = TC1_nFault_Pin;
  GPIO_InitStruct.Mode = LL_GPIO_MODE_OUTPUT;
  GPIO_InitStruct.Speed = LL_GPIO_SPEED_FREQ_LOW;
  GPIO_InitStruct.OutputType = LL_GPIO_OUTPUT_PUSHPULL;
  GPIO_InitStruct.Pull = LL_GPIO_PULL_NO;
  LL_GPIO_Init(TC1_nFault_GPIO_Port, &GPIO_InitStruct);

  /**/
  GPIO_InitStruct.Pin = TC1_cs_Pin;
  GPIO_InitStruct.Mode = LL_GPIO_MODE_OUTPUT;
  GPIO_InitStruct.Speed = LL_GPIO_SPEED_FREQ_LOW;
  GPIO_InitStruct.OutputType = LL_GPIO_OUTPUT_PUSHPULL;
  GPIO_InitStruct.Pull = LL_GPIO_PULL_NO;
  LL_GPIO_Init(TC1_cs_GPIO_Port, &GPIO_InitStruct);

  /**/
  GPIO_InitStruct.Pin = TC1_nReady_Pin;
  GPIO_InitStruct.Mode = LL_GPIO_MODE_OUTPUT;
  GPIO_InitStruct.Speed = LL_GPIO_SPEED_FREQ_LOW;
  GPIO_InitStruct.OutputType = LL_GPIO_OUTPUT_PUSHPULL;
  GPIO_InitStruct.Pull = LL_GPIO_PULL_NO;
  LL_GPIO_Init(TC1_nReady_GPIO_Port, &GPIO_InitStruct);

  /**/
  GPIO_InitStruct.Pin = TC2_nFault_Pin;
  GPIO_InitStruct.Mode = LL_GPIO_MODE_OUTPUT;
  GPIO_InitStruct.Speed = LL_GPIO_SPEED_FREQ_LOW;
  GPIO_InitStruct.OutputType = LL_GPIO_OUTPUT_PUSHPULL;
  GPIO_InitStruct.Pull = LL_GPIO_PULL_NO;
  LL_GPIO_Init(TC2_nFault_GPIO_Port, &GPIO_InitStruct);

  /**/
  GPIO_InitStruct.Pin = TC2_cs_Pin;
  GPIO_InitStruct.Mode = LL_GPIO_MODE_OUTPUT;
  GPIO_InitStruct.Speed = LL_GPIO_SPEED_FREQ_LOW;
  GPIO_InitStruct.OutputType = LL_GPIO_OUTPUT_PUSHPULL;
  GPIO_InitStruct.Pull = LL_GPIO_PULL_NO;
  LL_GPIO_Init(TC2_cs_GPIO_Port, &GPIO_InitStruct);

  /**/
  GPIO_InitStruct.Pin = TC2_nReady_Pin;
  GPIO_InitStruct.Mode = LL_GPIO_MODE_OUTPUT;
  GPIO_InitStruct.Speed = LL_GPIO_SPEED_FREQ_LOW;
  GPIO_InitStruct.OutputType = LL_GPIO_OUTPUT_PUSHPULL;
  GPIO_InitStruct.Pull = LL_GPIO_PULL_NO;
  LL_GPIO_Init(TC2_nReady_GPIO_Port, &GPIO_InitStruct);

}

/* USER CODE BEGIN 4 */
#if (configGENERATE_RUN_TIME_STATS == 1)
	void StartStatsTimer(void) {
		HAL_TIM_Base_Start(&htim3);	// replace htim2 with your selected timer
	}

	uint32_t GetStatsTimerCount(void) {
		return __HAL_TIM_GET_COUNTER(&htim3);	// replace htim2 with your selected timer
	}
#endif
/* USER CODE END 4 */

void StartDefaultTask(void const * argument)
{
  for(;;)
  {
    osDelay(1);
  }
}

void HAL_TIM_PeriodElapsedCallback(TIM_HandleTypeDef *htim)
{
  if (htim->Instance == TIM2)
  {
    HAL_IncTick();
  }
}

void Error_Handler(void)
{
  __disable_irq();
  while (1)
  {
  }
}
